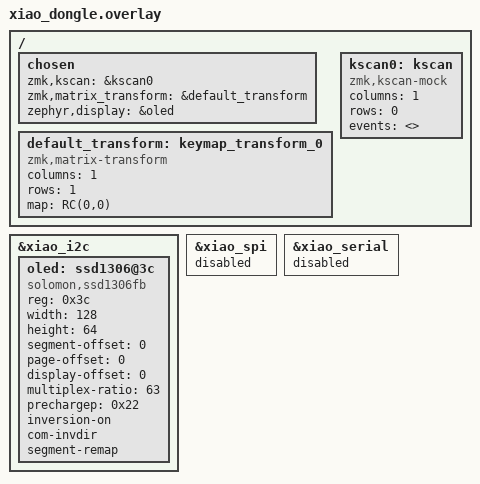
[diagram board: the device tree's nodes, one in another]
/*
 * Generic XIAO BLE dongle shield.
 * Seeeduino XIAO BLE as a split central with:
 *   - Mock kscan (no physical keys)
 *   - SSD1306 128x64 OLED on I2C (0x3c)
 *   - SPI and serial disabled
 *   - Placeholder transform (override in user config)
 */

#include <dt-bindings/zmk/matrix_transform.h>

/ {
    chosen {
        zmk,kscan = &kscan0;
        zmk,matrix_transform = &default_transform;
        zephyr,display = &oled;
    };

    default_transform: keymap_transform_0 {
        compatible = "zmk,matrix-transform";
        columns = <1>;
        rows = <1>;
        map = < RC(0,0) >;
    };

    kscan0: kscan {
        compatible = "zmk,kscan-mock";
        columns = <1>;
        rows = <0>;
        events = <>;
    };
};

&xiao_i2c {
    status = "okay";

    oled: ssd1306@3c {
        compatible = "solomon,ssd1306fb";
        reg = <0x3c>;
        width = <128>;
        height = <64>;
        segment-offset = <0>;
        page-offset = <0>;
        display-offset = <0>;
        multiplex-ratio = <63>;
        prechargep = <0x22>;
        inversion-on;
        com-invdir;
        segment-remap;
    };
};

&xiao_spi { status = "disabled"; };
&xiao_serial { status = "disabled"; };
